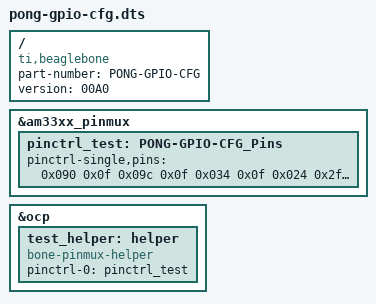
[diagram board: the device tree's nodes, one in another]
/*  
* Copyright (C) 2012 Texas Instruments Incorporated - http://www.ti.com/
*
* This program is free software; you can redistribute it and/or modify
* it under the terms of the GNU General Purpose License Version 2 as
* published by the Free Software Foundation
*
* Original from: github.com/jadonk/validation-scripts/blob/master/test-capemgr/ 
*
* GPIO CONFIG FOR PONG
*/

/dts-v1/;
/plugin/;

/{
       compatible = "ti,beaglebone", "ti,beaglebone-black";
       part-number = "PONG-GPIO-CFG";
       version = "00A0";

       fragment@0 {
             target = <&am33xx_pinmux>;
            
             __overlay__ {
                  pinctrl_test: PONG-GPIO-CFG_Pins {
            pinctrl-single,pins = <

                0x090 0x0f  /* P8_07 66 OUTPUT MODE7  dir */
                0x09c 0x0f  /* P8_09 69 OUTPUT  MODE7 step */       
                0x034 0x0f  /* P8_11 45 INPUT  MODE7  kick */
                0x024 0x2f  /* P8_13 23 INPUT  MODE7  limiit */
                0x03c 0x2f  /* P8_15 47 INPUT  MODE7  laser */

                0x094 0x0f  /* P8_08 67 OUTPUT  MODE7  dir  */
                0x098 0x0f  /* P8_10 68 OUTPUT  MODE7  step  */
                0x030 0x0f  /* P8_12 44 OUTPUT  MODE7  kicker  */
                0x028 0x2f  /* P8_14 26 INPUT  MODE7   limit*/              
                0x038 0x2f  /* P8_16 46 INPUT  MODE7  laser*/

                       
                   /* OUTPUT  GPIO(mode7) 0x07 pulldown, 0x17 pullup, 0x?f no pullup/down */
                   /* INPUT   GPIO(mode7) 0x27 pulldown, 0x37 pullup, 0x?f no pullup/down */

            >;
          };
             };
       };

       fragment@1 {
        target = <&ocp>;
        __overlay__ {
            test_helper: helper {
                compatible = "bone-pinmux-helper";
                pinctrl-names = "default";
                pinctrl-0 = <&pinctrl_test>;
                status = "okay";
            };
        };
    };
};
